# liliumSOC1_sysctrl register map
Vendor: Nordic Semiconductor; Series: liliumSOC1; File version: 1
Registers are 32-bit, read-write, reset 0x0 unless marked. A register's access mark holds for its fields unless they carry their own. Offsets are from the block's base; [hi:lo] are bit positions; lines under a group give offsets from that group; {n}, {i} and the like mark numbered series; 'fields as' and 'values as' point back to an identical list.

## PCRM_S — PCRM
Base 0x5F943000
{0x100+4i} EVENTS_REQUESTRISING[{i}] (i=0..31) — Description collection: Request rising for the consumer n
  [0] EVENTS_REQUESTRISING — Request rising for the consumer n
    0=NotGenerated (Event not generated); 1=Generated (Event generated)
{0x200+4i} EVENTS_REQUESTFALLING[{i}] (i=0..31) — Description collection: Request falling for the consumer n
  [0] EVENTS_REQUESTFALLING — Request falling for the consumer n
    values as EVENTS_REQUESTRISING[0].EVENTS_REQUESTRISING
{0x300+4i} EVENTS_LOADCHANGERAIL[{i}] (i=0..15) — Description collection: Load change on rail n
  [0] EVENTS_LOADCHANGERAIL — Load change on rail n
    values as EVENTS_REQUESTRISING[0].EVENTS_REQUESTRISING
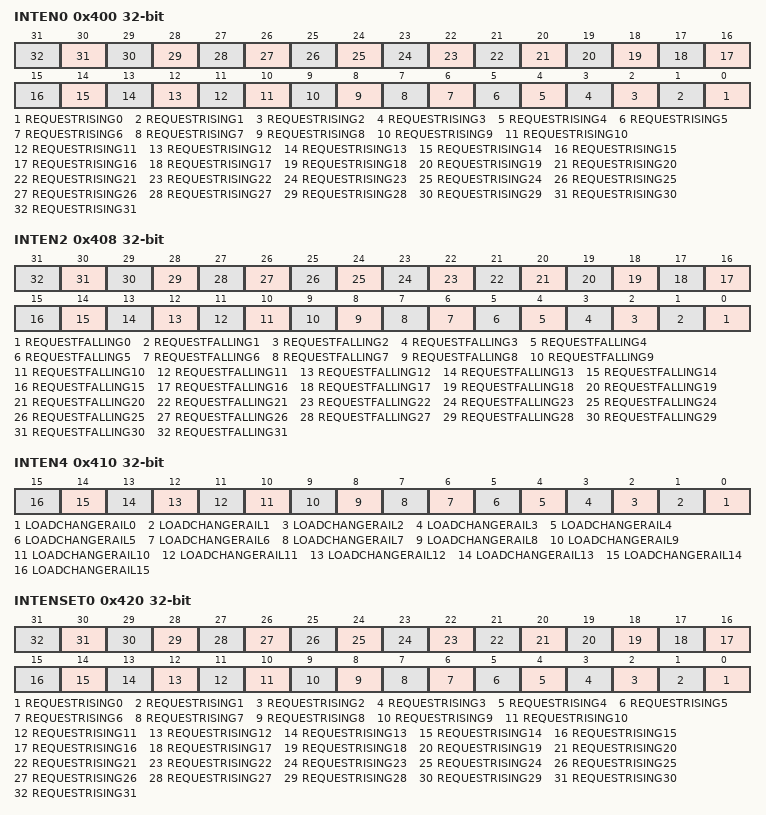
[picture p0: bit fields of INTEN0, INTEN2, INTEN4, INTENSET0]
0x400 INTEN0 — Enable or disable interrupt
  [all] fields
    0=Disabled; 1=Enabled
  [n] REQUESTRISING{n} (n=0..31) — Enable or disable interrupt for event REQUESTRISING[{n}]
0x404 INTEN1 — Enable or disable interrupt
0x408 INTEN2 — Enable or disable interrupt
  [all] fields
    0=Disabled; 1=Enabled
  [n] REQUESTFALLING{n} (n=0..31) — Enable or disable interrupt for event REQUESTFALLING[{n}]
0x40C INTEN3 — Enable or disable interrupt
0x410 INTEN4 — Enable or disable interrupt
  [all] fields
    0=Disabled; 1=Enabled
  [n] LOADCHANGERAIL{n} (n=0..15) — Enable or disable interrupt for event LOADCHANGERAIL[{n}]
{0x400+4i} INTEN{i} (i=5..7) — Enable or disable interrupt
0x420 INTENSET0 — Enable interrupt
  [all] fields
    on read: 0=Disabled (Read: Disabled); 1=Enabled (Read: Enabled) | on write: 1=Set (Enable)
  [n] REQUESTRISING{n} (n=0..31) — Write '1' to enable interrupt for event REQUESTRISING[{n}]
0x424 INTENSET1 — Enable interrupt
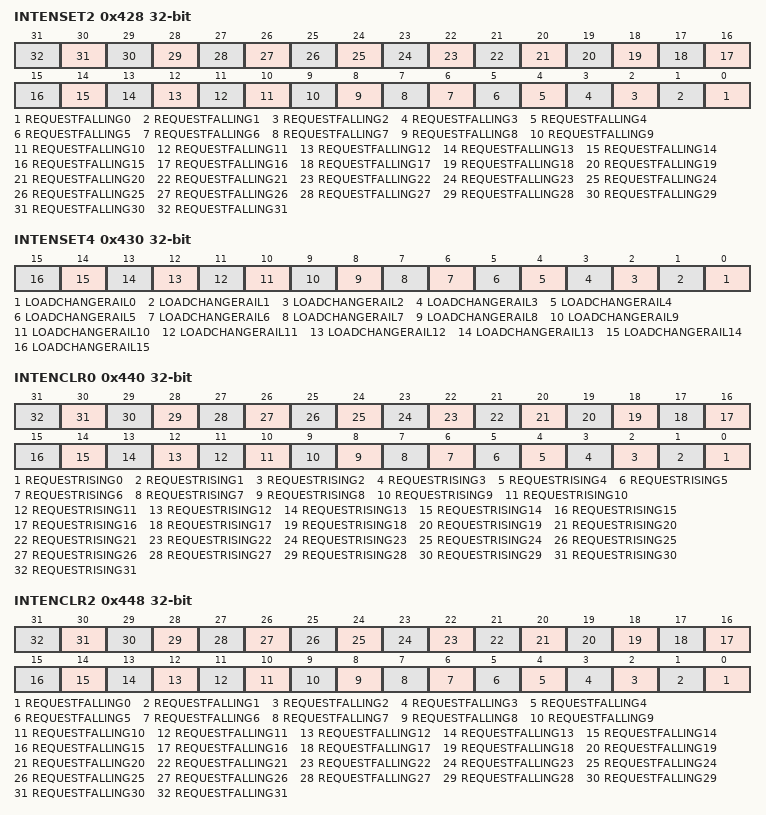
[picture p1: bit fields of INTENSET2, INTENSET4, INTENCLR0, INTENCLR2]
0x428 INTENSET2 — Enable interrupt
  [all] fields
    values as the fields of INTENSET0
  [n] REQUESTFALLING{n} (n=0..31) — Write '1' to enable interrupt for event REQUESTFALLING[{n}]
0x42C INTENSET3 — Enable interrupt
0x430 INTENSET4 — Enable interrupt
  [all] fields
    values as the fields of INTENSET0
  [n] LOADCHANGERAIL{n} (n=0..15) — Write '1' to enable interrupt for event LOADCHANGERAIL[{n}]
{0x420+4i} INTENSET{i} (i=5..7) — Enable interrupt
0x440 INTENCLR0 — Disable interrupt
  [all] fields
    on read: 0=Disabled (Read: Disabled); 1=Enabled (Read: Enabled) | on write: 1=Clear (Disable)
  [n] REQUESTRISING{n} (n=0..31) — Write '1' to disable interrupt for event REQUESTRISING[{n}]
0x444 INTENCLR1 — Disable interrupt
0x448 INTENCLR2 — Disable interrupt
  [all] fields
    values as the fields of INTENCLR0
  [n] REQUESTFALLING{n} (n=0..31) — Write '1' to disable interrupt for event REQUESTFALLING[{n}]
0x44C INTENCLR3 — Disable interrupt
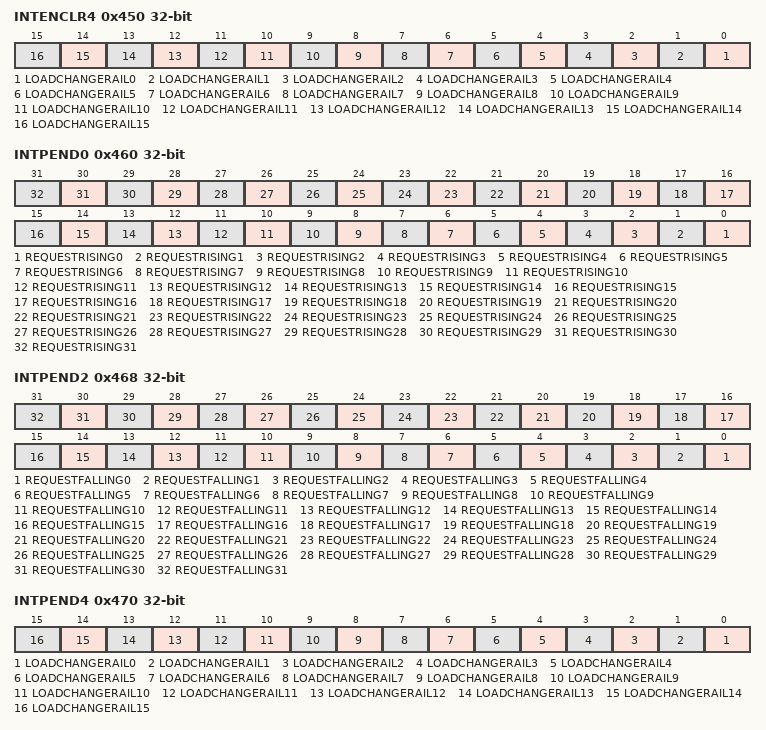
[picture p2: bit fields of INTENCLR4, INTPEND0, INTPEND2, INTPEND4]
0x450 INTENCLR4 — Disable interrupt
  [all] fields
    values as the fields of INTENCLR0
  [n] LOADCHANGERAIL{n} (n=0..15) — Write '1' to disable interrupt for event LOADCHANGERAIL[{n}]
{0x440+4i} INTENCLR{i} (i=5..7) — Disable interrupt
0x460 INTPEND0 ro — Pending interrupts
  [all] fields
    on read: 0=NotPending (Read: Not pending); 1=Pending (Read: Pending)
  [n] REQUESTRISING{n} (n=0..31) — Read pending status of interrupt for event REQUESTRISING[{n}]
0x464 INTPEND1 ro — Pending interrupts
0x468 INTPEND2 ro — Pending interrupts
  [all] fields
    values as the fields of INTPEND0
  [n] REQUESTFALLING{n} (n=0..31) — Read pending status of interrupt for event REQUESTFALLING[{n}]
0x46C INTPEND3 ro — Pending interrupts
0x470 INTPEND4 ro — Pending interrupts
  [all] fields
    values as the fields of INTPEND0
  [n] LOADCHANGERAIL{n} (n=0..15) — Read pending status of interrupt for event LOADCHANGERAIL[{n}]
{0x460+4i} INTPEND{i} ro (i=5..7) — Pending interrupts
0x600 REQUEST group — Unspecified
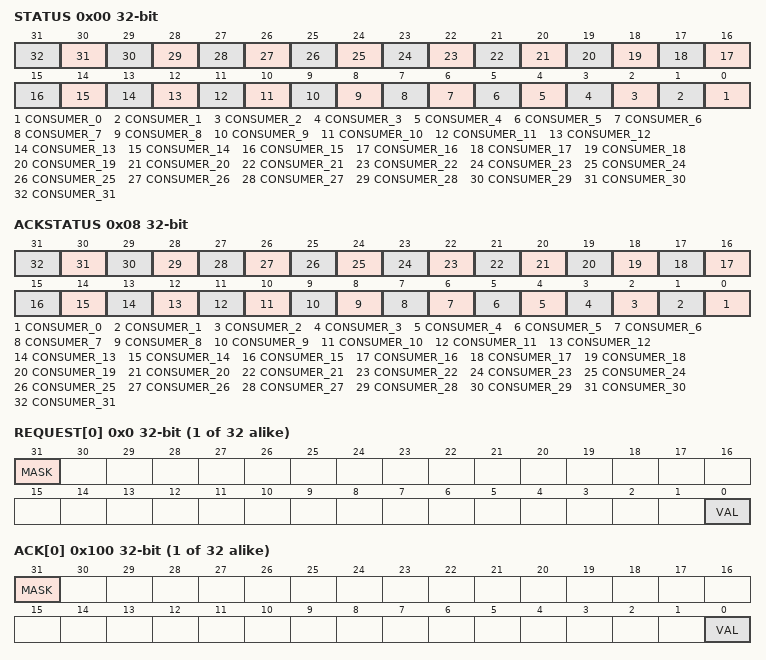
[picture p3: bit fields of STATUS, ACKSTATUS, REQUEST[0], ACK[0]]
  0x00 STATUS ro — Request status for consumers
    [all] fields
      0=Falling (Request falling); 1=Rising (Request rising)
    [n] CONSUMER_{n} (n=0..31) — Status of the request for consumer {n}
  0x08 ACKSTATUS ro — Ack status for the request for consumers
    [all] fields
      0=AckNotReceived; 1=AckReceived
    [n] CONSUMER_{n} (n=0..31) — Ack status of the request for consumer [{n}]
0x610 RAIL group — Unspecified
  {0x0+4j} STATUS[{j}] (j=0..15) ro — Description collection: Status of the rail n
    [7:0] VALUE — Estimated value for the rail n
0x650 CONFIG group — Unspecified
  {0x0+4j} LOAD[{j}] (j=0..31) — Description collection: Load configuration table for consumer for consumer n
    [9:0] VALUE — Threshold value for the load for consumer n
0x750 OVERRIDE group — Unspecified
  {0x0+4j} REQUEST[{j}] (j=0..31) — Description collection: Override the request for consumer n
    [31] MASK — Mask to override the request for consumer n
      0=Mask (Override value masked); 1=UnMask (Override value unmasked)
    [0] VAL — Override value for the request for consumer n
      0=Clear (Request cleared); 1=Set (Request set)
  {0x100+4j} ACK[{j}] (j=0..31) — Description collection: Override the Ack for the request for consumer n
    [31] MASK — Mask to override the Ack for the request for consumer n
      values as OVERRIDE.REQUEST[0].MASK
    [0] VAL — Override the Ack value for the request for consumer n
      0=Clear (Ack clear); 1=Set (Ack set)
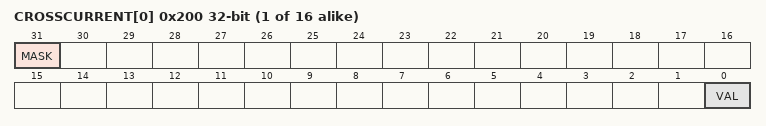
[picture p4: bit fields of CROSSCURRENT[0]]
  {0x200+4j} CROSSCURRENT[{j}] (j=0..15) — Description collection: Override the cross current for rail n
    [31] MASK — Mask to override the cross current value for rail n
      values as OVERRIDE.REQUEST[0].MASK
    [0] VAL — Override value for the cross current for rail n
      0=Disabled (Cross current disabled); 1=Enabled (Cross current enabled)
